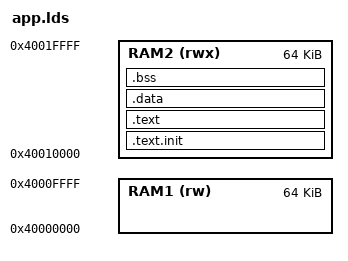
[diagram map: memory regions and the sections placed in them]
/*
 * Copyright (C) 2022 - Tillitis AB
 * SPDX-License-Identifier: GPL-2.0-only
 */

OUTPUT_ARCH( "riscv" )
ENTRY(_start)

MEMORY
{
	RAM1 (rw)   : ORIGIN = 0x40000000, LENGTH = 0x10000 /* 64 KB */
	RAM2 (rwx)   : ORIGIN = 0x40010000, LENGTH = 0x10000 /* 64 KB */
}

SECTIONS
{
	.text.init :
	{
		*(.text.init)
	} >RAM2

	.text :
	{
		. = ALIGN(4);
		*(.text)           /* .text sections (code) */
		*(.text*)          /* .text* sections (code) */
		*(.rodata)         /* .rodata sections (constants, strings, etc.) */
		*(.rodata*)        /* .rodata* sections (constants, strings, etc.) */
		*(.srodata)        /* .rodata sections (constants, strings, etc.) */
		*(.srodata*)       /* .rodata* sections (constants, strings, etc.) */
		. = ALIGN(4);
		_etext = .;
		_sidata = _etext;
	} >RAM2

	.data : AT (_etext)
	{
		. = ALIGN(4);
		_sdata = .;
		. = ALIGN(4);
		*(.data)           /* .data sections */
		*(.data*)          /* .data* sections */
		*(.sdata)           /* .sdata sections */
		*(.sdata*)          /* .sdata* sections */
		. = ALIGN(4);
		_edata = .;

	} >RAM2

	/* Uninitialized data section */
	.bss :
	{
		. = ALIGN(4);
		_sbss = .;
		*(.bss)
		*(.bss*)
		*(.sbss)
		*(.sbss*)
		*(COMMON)

		. = ALIGN(4);
		_ebss = .;
	} >RAM2
	/* Init stack to start directly under RAM2, see crt0.s */
}
